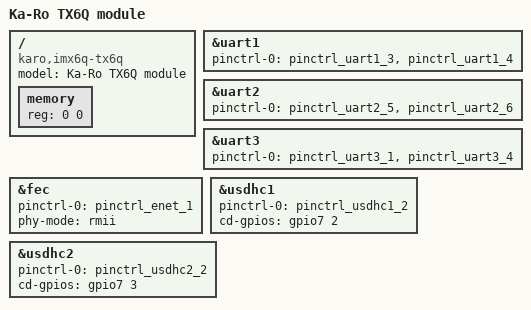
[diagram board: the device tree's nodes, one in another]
/*
 * Copyright 2012 Freescale Semiconductor, Inc.
 * Copyright 2011 Linaro Ltd.
 *
 * The code contained herein is licensed under the GNU General Public
 * License. You may obtain a copy of the GNU General Public License
 * Version 2 or later at the following locations:
 *
 * http://www.opensource.org/licenses/gpl-license.html
 * http://www.gnu.org/copyleft/gpl.html
 */

/dts-v1/;
#include "mx6dl.dtsi"

/ {
	model = "Ka-Ro TX6Q module";
	compatible = "karo,imx6q-tx6q", "fsl,imx6q";

	memory {
		reg = <0 0>; /* filled in by U-Boot */
	};
};

&uart1 {
	pinctrl-names = "default";
	pinctrl-0 = <&pinctrl_uart1_3 &pinctrl_uart1_4>;
	status = "okay";
};

&uart2 {
	pinctrl-names = "default";
	pinctrl-0 = <&pinctrl_uart2_5 &pinctrl_uart2_6>;
	status = "okay";
};

&uart3 {
	pinctrl-names = "default";
	pinctrl-0 = <&pinctrl_uart3_1 &pinctrl_uart3_4>;
	status = "okay";
};

&fec {
	pinctrl-names = "default";
	pinctrl-0 = <&pinctrl_enet_1>;
	phy-mode = "rmii";
	status = "okay";
};

&usdhc1 {
	pinctrl-names = "default";
	pinctrl-0 = <&pinctrl_usdhc1_2>;
	cd-gpios = <&gpio7 2 0>;
	status = "okay";
};

&usdhc2 {
	pinctrl-names = "default";
	pinctrl-0 = <&pinctrl_usdhc2_2>;
	cd-gpios = <&gpio7 3 0>;
	status = "okay";
};
